# PRM_CEFUSE register map
Vendor: Texas Instruments
Peripheral module from a debugger description file (folder am335x).
Registers are 32-bit, access per field, no defined reset value unless marked. A register's access mark holds for its fields unless they carry their own. Offsets are as the file gives them; lines under a group give offsets from that group; [hi:lo] are bit positions; {n}, {i} and the like mark numbered series; 'fields as' and 'values as' point back to an identical list; <NAME> marks a mode.

## PRM_CEFUSE
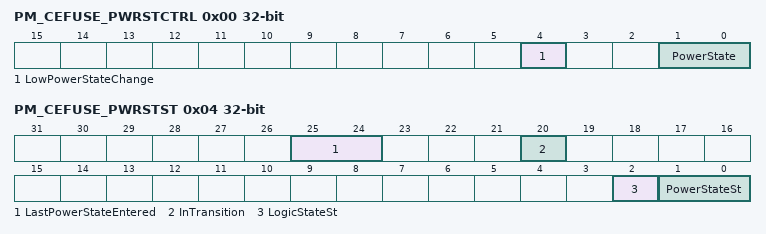
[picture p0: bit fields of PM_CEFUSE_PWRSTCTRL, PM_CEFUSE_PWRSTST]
0x00 PM_CEFUSE_PWRSTCTRL — This register controls the CEFUSE power state to reach upon a domain sleep transition
  [4] LowPowerStateChange rw — Power state change request when domain has already performed a sleep transition. Allows going into deeper low power state without waking up the power domain.
    0=DIS (Do not request a low power state change.); 1=EN (Request a low power state change. This bit is automatically cleared when the power state is effectively changed or when power state is ON.)
  [1:0] PowerState rw — Power state control
    0=OFF (OFF state); 2=INACT (INACTIVE state); 3=ON (ON State)
0x04 PM_CEFUSE_PWRSTST — This register provides a status on the current CEFUSE power domain state. [warm reset insensitive]
  [25:24] LastPowerStateEntered rw — Last low power state entered. Set to 0x3 upon write of the same only. This register is intended for debug purpose only.
    0=OFF (Power domain was previously OFF); 1=ON (Power domain was previously ON-ACTIVE)
  [20] InTransition ro — Domain transition status
    0=No (No on-going transition on power domain); 1=Ongoing (Power domain transition is in progress.)
  [2] LogicStateSt ro — Logic state status
    0=OFF (Logic in domain is OFF); 1=ON (Logic in domain is ON)
  [1:0] PowerStateSt ro — Current power state status
    0=OFF (Power domain is OFF); 1=RET (Power domain is in RETENTION); 2=INACTIVE (Power domain is ON-INACTIVE); 3=ON (Power domain is ON-ACTIVE)
